VERSION ""

NS_ :

BS_:

BU_: T_Panel PC

BO_ 5 INFO_PANEL: 5 T_Panel
 SG_ alive_counter : 32|4@1+ (1,0) [0|15] "" Vector__XXX
 SG_ INFO_ALIVE_PANEL : 0|32@1+ (1,0) [0|4294967295] ""  PC

BO_ 4 INFO_PC: 1 PC
 SG_ INFO_ALIVE_PC : 0|8@1+ (1,0) [0|255] ""  T_Panel

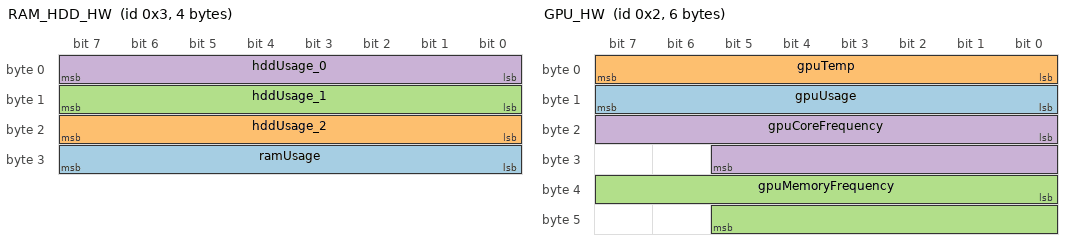
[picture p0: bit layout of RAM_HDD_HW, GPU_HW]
BO_ 3 RAM_HDD_HW: 4 T_Panel
 SG_ ramUsage : 24|8@1+ (1,0) [0|255] ""  PC
 SG_ hddUsage_2 : 16|8@1+ (1,0) [0|255] ""  PC
 SG_ hddUsage_1 : 8|8@1+ (1,0) [0|255] ""  PC
 SG_ hddUsage_0 : 0|8@1+ (1,0) [0|255] ""  PC

BO_ 2 GPU_HW: 6 T_Panel
 SG_ gpuUsage : 8|8@1+ (1,0) [0|255] ""  PC
 SG_ gpuTemp : 0|8@1+ (1,0) [0|255] ""  PC
 SG_ gpuMemoryFrequency : 32|14@1+ (1,0) [0|16383] ""  PC
 SG_ gpuCoreFrequency : 16|14@1+ (1,0) [0|16383] ""  PC

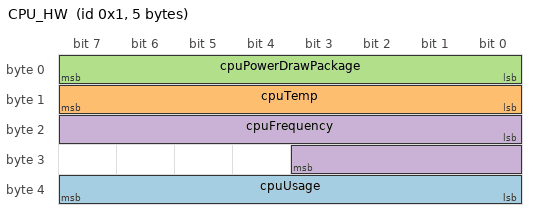
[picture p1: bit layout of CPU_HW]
BO_ 1 CPU_HW: 5 T_Panel
 SG_ cpuUsage : 32|8@1+ (1,0) [0|255] ""  PC
 SG_ cpuTemp : 8|8@1+ (1,0) [0|255] ""  PC
 SG_ cpuPowerDrawPackage : 0|8@1+ (1,0) [0|255] ""  PC
 SG_ cpuFrequency : 16|12@1+ (1,0) [0|4095] ""  PC

CM_ BO_ 3 "OpenHardwareMonitor data for RAM and HDD";
CM_ BO_ 2 "OpenHardwareMonitor data for GPU";
CM_ BO_ 1 "OpenHardwareMonitor data for CPU";
BA_DEF_  "BusType" STRING ;
BA_DEF_DEF_  "BusType" "CAN";
